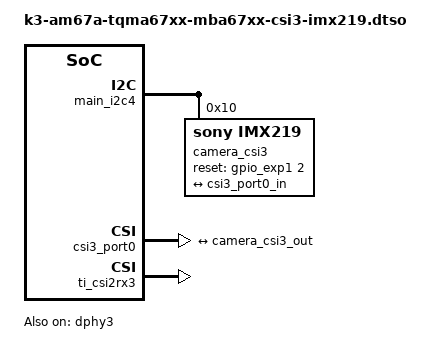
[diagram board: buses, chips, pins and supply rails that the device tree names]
// SPDX-License-Identifier: GPL-2.0-only OR MIT
/*
 * Copyright (C) 2023-2024 Texas Instruments Incorporated - https://www.ti.com/
 * Copyright (c) 2025 TQ-Systems GmbH <linux@ew.tq-group.com>, D-82229 Seefeld, Germany.
 * Author: Matthias Schiffer
 *
 * IMX219 (RPi v2) Camera Module on MBa67xx
 */

/dts-v1/;
/plugin/;

#include <dt-bindings/gpio/gpio.h>
#include <dt-bindings/media/video-interfaces.h>

&{/} {
	clk_csi3_imx219: clk-csi3-imx219 {
		compatible = "fixed-clock";
		#clock-cells = <0>;
		clock-frequency = <24000000>;
	};
};

&main_i2c4 {
	#address-cells = <1>;
	#size-cells = <0>;
	status = "okay";

	camera_csi3: camera@10 {
		compatible = "sony,imx219";
		reg = <0x10>;

		clocks = <&clk_csi3_imx219>;
		clock-names = "xclk";

		reset-gpios = <&gpio_exp1 2 GPIO_ACTIVE_HIGH>;

		port {
			camera_csi3_out: endpoint {
				remote-endpoint = <&csi3_port0_in>;
				link-frequencies = /bits/ 64 <456000000>;
				clock-lanes = <0>;
				data-lanes = <1 2>;
			};
		};
	};
};

&csi3_port0 {
	status = "okay";

	csi3_port0_in: endpoint {
		remote-endpoint = <&camera_csi3_out>;
		bus-type = <MEDIA_BUS_TYPE_CSI2_DPHY>;
		clock-lanes = <0>;
		data-lanes = <1 2>;
	};
};

&ti_csi2rx3 {
	status = "okay";
};

&dphy3 {
	status = "okay";
};
